# EFR32ZG14P731F256GM32 register map
File version: 4.0.0
CPU: CM4 r0p1, little endian, no MPU, no FPU, 0x3 interrupt priority bits, 0x0 interrupts
Registers are 32-bit, read-write, reset 0x0 unless marked. A register's access mark holds for its fields unless they carry their own. Offsets are from the block's base; [hi:lo] are bit positions; {n}, {i} and the like mark numbered series; 'fields as' and 'values as' point back to an identical list.

## WDOG0
Base 0x40052000
Same registers: WDOG1 0x40052400
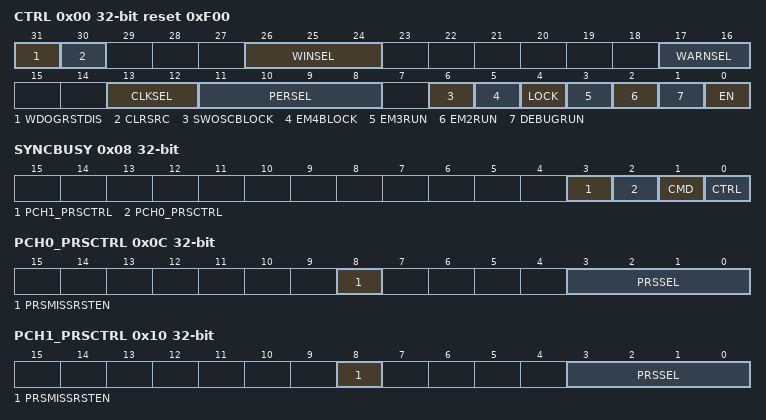
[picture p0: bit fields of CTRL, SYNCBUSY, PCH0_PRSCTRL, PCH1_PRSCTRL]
0x00 CTRL reset 0xF00 — Control Register
  [31] WDOGRSTDIS — Watchdog Reset Disable
  [30] CLRSRC — Watchdog Clear Source
  [26:24] WINSEL — Watchdog Illegal Window Select
  [17:16] WARNSEL — Watchdog Timeout Period Select
  [13:12] CLKSEL — Watchdog Clock Select
    0=ULFRCO; 1=LFRCO; 2=LFXO; 3=HFCORECLK
  [11:8] PERSEL — Watchdog Timeout Period Select
  [6] SWOSCBLOCK — Software Oscillator Disable Block
  [5] EM4BLOCK — Energy Mode 4 Block
  [4] LOCK — Configuration Lock
  [3] EM3RUN — Energy Mode 3 Run Enable
  [2] EM2RUN — Energy Mode 2 Run Enable
  [1] DEBUGRUN — Debug Mode Run Enable
  [0] EN — Watchdog Timer Enable
0x04 CMD wo — Command Register
  [0] CLEAR — Watchdog Timer Clear
0x08 SYNCBUSY ro — Synchronization Busy Register
  [3] PCH1_PRSCTRL — PCH1_PRSCTRL Register Busy
  [2] PCH0_PRSCTRL — PCH0_PRSCTRL Register Busy
  [1] CMD — CMD Register Busy
  [0] CTRL — CTRL Register Busy
0x0C PCH0_PRSCTRL — PRS Control Register
  [8] PRSMISSRSTEN — PRS Missing Event Will Trigger a Watchdog Reset
  [3:0] PRSSEL — PRS Channel PRS Select
    {v}=PRSCH{v} (PRS Channel {v} selected as input) (v=0..11)
0x10 PCH1_PRSCTRL — PRS Control Register
  fields as PCH0_PRSCTRL
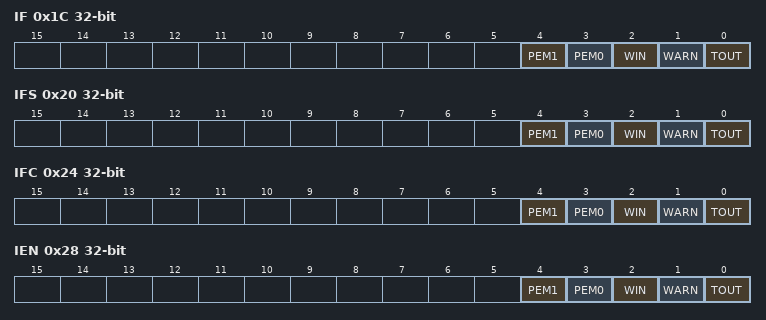
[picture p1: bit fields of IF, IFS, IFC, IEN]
0x1C IF ro — Watchdog Interrupt Flags
  [4] PEM1 — PRS Channel One Event Missing Interrupt Flag
  [3] PEM0 — PRS Channel Zero Event Missing Interrupt Flag
  [2] WIN — WDOG Window Interrupt Flag
  [1] WARN — WDOG Warning Timeout Interrupt Flag
  [0] TOUT — WDOG Timeout Interrupt Flag
0x20 IFS wo — Interrupt Flag Set Register
  [4] PEM1 — Set PEM1 Interrupt Flag
  [3] PEM0 — Set PEM0 Interrupt Flag
  [2] WIN — Set WIN Interrupt Flag
  [1] WARN — Set WARN Interrupt Flag
  [0] TOUT — Set TOUT Interrupt Flag
0x24 IFC wo — Interrupt Flag Clear Register
  [4] PEM1 — Clear PEM1 Interrupt Flag
  [3] PEM0 — Clear PEM0 Interrupt Flag
  [2] WIN — Clear WIN Interrupt Flag
  [1] WARN — Clear WARN Interrupt Flag
  [0] TOUT — Clear TOUT Interrupt Flag
0x28 IEN — Interrupt Enable Register
  [4] PEM1 — PEM1 Interrupt Enable
  [3] PEM0 — PEM0 Interrupt Enable
  [2] WIN — WIN Interrupt Enable
  [1] WARN — WARN Interrupt Enable
  [0] TOUT — TOUT Interrupt Enable

## SMU
Base 0x40022000
0x0C IF ro — Interrupt Flag Register
  [0] PPUPRIV — PPU Privilege Interrupt Flag
0x10 IFS wo — Interrupt Flag Set Register
  [0] PPUPRIV — Set PPUPRIV Interrupt Flag
0x14 IFC wo — Interrupt Flag Clear Register
  [0] PPUPRIV — Clear PPUPRIV Interrupt Flag
0x18 IEN — Interrupt Enable Register
  [0] PPUPRIV — PPUPRIV Interrupt Enable
0x40 PPUCTRL — PPU Control Register
  [0] ENABLE
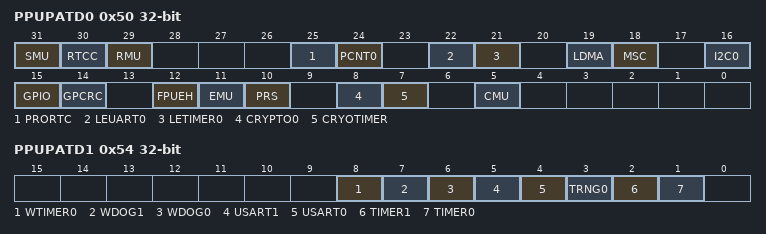
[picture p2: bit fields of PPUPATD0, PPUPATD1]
0x50 PPUPATD0 — PPU Privilege Access Type Descriptor 0
  [31] SMU — Security Management Unit access control bit
  [30] RTCC — Real-Time Counter and Calendar access control bit
  [29] RMU — Reset Management Unit access control bit
  [25] PRORTC — Protocol Real-Time Counter access control bit
  [24] PCNT0 — Pulse Counter 0 access control bit
  [22] LEUART0 — Low Energy UART 0 access control bit
  [21] LETIMER0 — Low Energy Timer 0 access control bit
  [19] LDMA — Linked Direct Memory Access Controller access control bit
  [18] MSC — Memory System Controller access control bit
  [16] I2C0 — I2C 0 access control bit
  [15] GPIO — General purpose Input/Output access control bit
  [14] GPCRC — General Purpose CRC access control bit
  [12] FPUEH — FPU Exception Handler access control bit
  [11] EMU — Energy Management Unit access control bit
  [10] PRS — Peripheral Reflex System access control bit
  [8] CRYPTO0 — Advanced Encryption Standard Accelerator 0 access control bit
  [7] CRYOTIMER — CRYOTIMER access control bit
  [5] CMU — Clock Management Unit access control bit
0x54 PPUPATD1 — PPU Privilege Access Type Descriptor 1
  [8] WTIMER0 — Wide Timer 0 access control bit
  [7] WDOG1 — Watchdog 1 access control bit
  [6] WDOG0 — Watchdog 0 access control bit
  [5] USART1 — Universal Synchronous/Asynchronous Receiver/Transmitter 1 access control bit
  [4] USART0 — Universal Synchronous/Asynchronous Receiver/Transmitter 0 access control bit
  [3] TRNG0 — True Random Number Generator 0 access control bit
  [2] TIMER1 — Timer 1 access control bit
  [1] TIMER0 — Timer 0 access control bit
0x90 PPUFS ro — PPU Fault Status
  [6:0] PERIPHID
    5=CMU (Clock Management Unit); 7=CRYOTIMER; 8=CRYPTO0 (Advanced Encryption Standard Accelerator 0); 10=PRS (Peripheral Reflex System); 11=EMU (Energy Management Unit); 12=FPUEH (FPU Exception Handler); 14=GPCRC (General Purpose CRC); 15=GPIO (General purpose Input/Output); 16=I2C0; 18=MSC (Memory System Controller); 19=LDMA (Linked Direct Memory Access Controller); 21=LETIMER0 (Low Energy Timer 0); 22=LEUART0 (Low Energy UART 0); 24=PCNT0 (Pulse Counter 0); 25=PRORTC (Protocol Real-Time Counter); 29=RMU (Reset Management Unit); 30=RTCC (Real-Time Counter and Calendar); 31=SMU (Security Management Unit); 33=TIMER0; 34=TIMER1; 35=TRNG0 (True Random Number Generator 0); 36=USART0 (Universal Synchronous/Asynchronous Receiver/Transmitter 0); 37=USART1 (Universal Synchronous/Asynchronous Receiver/Transmitter 1); 38=WDOG0 (Watchdog 0); 39=WDOG1 (Watchdog 1); 40=WTIMER0 (Wide Timer 0)

## TRNG0
Base 0x4001D000
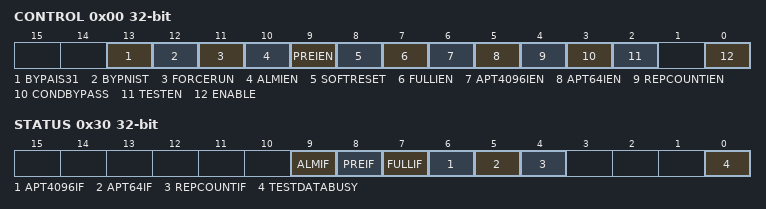
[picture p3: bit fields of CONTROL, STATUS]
0x00 CONTROL — Main Control Register
  [13] BYPAIS31 — AIS31 Start-up Test Bypass.
  [12] BYPNIST — NIST Start-up Test Bypass.
  [11] FORCERUN — Oscillator Force Run
  [10] ALMIEN — Interrupt enable for AIS31 noise alarm
  [9] PREIEN — Interrupt enable for AIS31 preliminary noise alarm
  [8] SOFTRESET — Software Reset
  [7] FULLIEN — Interrupt Enable for FIFO Full
  [6] APT4096IEN — Interrupt Enable for Adaptive Proportion Test Failure (4096-sample Window)
  [5] APT64IEN — Interrupt Enable for Adaptive Proportion Test Failure (64-sample Window)
  [4] REPCOUNTIEN — Interrupt Enable for Repetition Count Test Failure
  [3] CONDBYPASS — Conditioning Bypass
  [2] TESTEN — Test Enable
  [0] ENABLE — TRNG Module Enable
0x04 FIFOLEVEL ro read-has-side-effects
  [31:0] VALUE — FIFO Level
0x0C FIFODEPTH ro reset 0x40
  [31:0] VALUE — FIFO Depth.
{0x10+4i} KEY{i} (i=0..3) — Key Register {i}
  [31:0] VALUE — Key {i}
0x20 TESTDATA
  [31:0] VALUE — Test data input to conditioning function or to the continuous tests
0x30 STATUS
  [9] ALMIF ro — AIS31 Noise Alarm interrupt status
  [8] PREIF — AIS31 Preliminary Noise Alarm interrupt status
  [7] FULLIF ro — FIFO Full Interrupt Status
  [6] APT4096IF ro — Adaptive Proportion test failure (4096-sample window) interrupt status
  [5] APT64IF ro — Adaptive Proportion test failure (64-sample window) interrupt status
  [4] REPCOUNTIF ro — Repetition Count Test Interrupt Status
  [0] TESTDATABUSY ro
0x34 INITWAITVAL reset 0xFF — Initial Wait Counter
  [7:0] VALUE — Wait counter value
0x100 FIFO ro read-has-side-effects — FIFO Data
  [31:0] VALUE — FIFO Read Data
